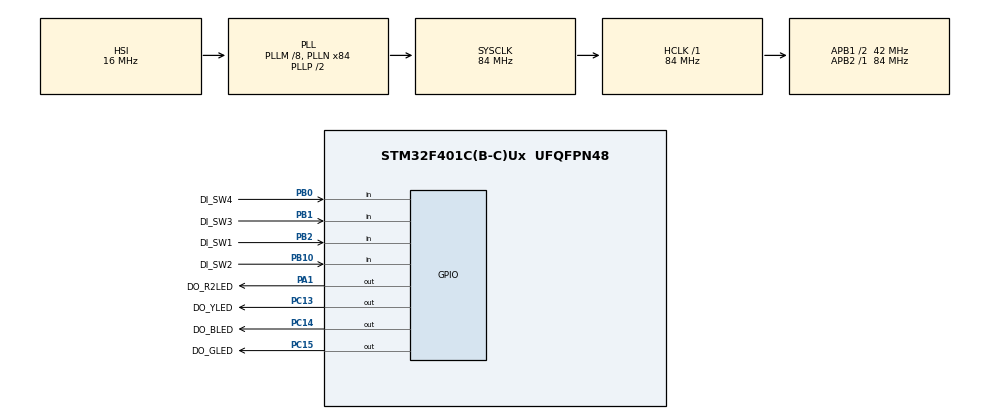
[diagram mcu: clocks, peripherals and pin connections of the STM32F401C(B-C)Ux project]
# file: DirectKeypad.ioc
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Mcu.Family=STM32F4
Mcu.Name=STM32F401C(B-C)Ux
Mcu.Package=UFQFPN48
NVIC.PriorityGroup=NVIC_PRIORITYGROUP_4
PA1.GPIO_Label=DO_R2LED
PA1.Signal=GPIO_Output
PA13.Mode=Serial_Wire
PA13.Signal=SYS_JTMS-SWDIO
PA14.Mode=Serial_Wire
PA14.Signal=SYS_JTCK-SWCLK
PB0.GPIO_Label=DI_SW4
PB0.GPIO_PuPd=GPIO_PULLUP
PB0.Signal=GPIO_Input
PB1.GPIO_Label=DI_SW3
PB1.GPIO_PuPd=GPIO_PULLUP
PB1.Signal=GPIO_Input
PB10.GPIO_Label=DI_SW2
PB10.GPIO_PuPd=GPIO_PULLUP
PB10.Signal=GPIO_Input
PB2.GPIO_Label=DI_SW1
PB2.GPIO_PuPd=GPIO_PULLUP
PB2.Signal=GPIO_Input
PC13-ANTI_TAMP.GPIO_Label=DO_YLED
PC13-ANTI_TAMP.Signal=GPIO_Output
PC14-OSC32_IN.GPIO_Label=DO_BLED
PC14-OSC32_IN.Signal=GPIO_Output
PC15-OSC32_OUT.GPIO_Label=DO_GLED
PC15-OSC32_OUT.Signal=GPIO_Output
PH0\ -\ OSC_IN.Mode=HSE-External-Oscillator
PH0\ -\ OSC_IN.Signal=RCC_OSC_IN
PH1\ -\ OSC_OUT.Mode=HSE-External-Oscillator
PH1\ -\ OSC_OUT.Signal=RCC_OSC_OUT
ProjectManager.HeapSize=0x200
ProjectManager.StackSize=0x400
ProjectManager.TargetToolchain=STM32CubeIDE
RCC.48MHZClocksFreq_Value=42000000
RCC.AHBFreq_Value=84000000
RCC.APB1CLKDivider=RCC_HCLK_DIV2
RCC.APB1Freq_Value=42000000
RCC.APB1TimFreq_Value=84000000
RCC.APB2Freq_Value=84000000
RCC.APB2TimFreq_Value=84000000
RCC.CortexFreq_Value=84000000
RCC.HCLKFreq_Value=84000000
RCC.HSE_VALUE=25000000
RCC.HSI_VALUE=16000000
RCC.LSE_VALUE=32768
RCC.PLLM=8
RCC.PLLN=84
RCC.SYSCLKFreq_VALUE=84000000
RCC.SYSCLKSource=RCC_SYSCLKSOURCE_PLLCLK
RCC.VCOOutputFreq_Value=168000000
board=custom

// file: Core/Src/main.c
/* USER CODE BEGIN Header */
/**
  ******************************************************************************
  * @file           : main.c
  * @brief          : Main program body
  ******************************************************************************
  * @attention
  *
  * Copyright (c) 2024 STMicroelectronics.
  * All rights reserved.
  *
  * This software is licensed under terms that can be found in the LICENSE file
  * in the root directory of this software component.
  * If no LICENSE file comes with this software, it is provided AS-IS.
  *
  ******************************************************************************
  */
/* USER CODE END Header */
#include "main.h"

void SystemClock_Config(void);
static void MX_GPIO_Init(void);

int main(void)
{

  /* MCU Configuration--------------------------------------------------------*/

  /* Reset of all peripherals, Initializes the Flash interface and the Systick. */
  HAL_Init();

  /* Configure the system clock */
  SystemClock_Config();

  /* Initialize all configured peripherals */
  MX_GPIO_Init();

  /* Infinite loop */
  /* USER CODE BEGIN WHILE */
  while (1)
  {
	  if(HAL_GPIO_ReadPin(DI_SW1_GPIO_Port, DI_SW1_Pin)==0)
	  {
		  HAL_GPIO_TogglePin(DO_R2LED_GPIO_Port, DO_R2LED_Pin);
		  HAL_Delay(200);
	  }
	  else if(HAL_GPIO_ReadPin(DI_SW2_GPIO_Port, DI_SW2_Pin)==0)
	  {
		  HAL_GPIO_TogglePin(DO_GLED_GPIO_Port, DO_GLED_Pin);
		  HAL_Delay(200);
	  }
	  else if(HAL_GPIO_ReadPin(DI_SW3_GPIO_Port, DI_SW3_Pin)==0)
	  {
		  HAL_GPIO_TogglePin(DO_BLED_GPIO_Port, DO_BLED_Pin);
		  HAL_Delay(200);
	  }
	  else if(HAL_GPIO_ReadPin(DI_SW4_GPIO_Port, DI_SW4_Pin)==0)
	  {
		  HAL_GPIO_TogglePin(DO_YLED_GPIO_Port, DO_YLED_Pin);
		  HAL_Delay(200);
	  }
    /* USER CODE END WHILE */

  }
}

void SystemClock_Config(void)
{
  RCC_OscInitTypeDef RCC_OscInitStruct = {0};
  RCC_ClkInitTypeDef RCC_ClkInitStruct = {0};

  /** Configure the main internal regulator output voltage
  */
  __HAL_RCC_PWR_CLK_ENABLE();
  __HAL_PWR_VOLTAGESCALING_CONFIG(PWR_REGULATOR_VOLTAGE_SCALE2);
  /** Initializes the RCC Oscillators according to the specified parameters
  * in the RCC_OscInitTypeDef structure.
  */
  RCC_OscInitStruct.OscillatorType = RCC_OSCILLATORTYPE_HSI;
  RCC_OscInitStruct.HSIState = RCC_HSI_ON;
  RCC_OscInitStruct.HSICalibrationValue = RCC_HSICALIBRATION_DEFAULT;
  RCC_OscInitStruct.PLL.PLLState = RCC_PLL_ON;
  RCC_OscInitStruct.PLL.PLLSource = RCC_PLLSOURCE_HSI;
  RCC_OscInitStruct.PLL.PLLM = 8;
  RCC_OscInitStruct.PLL.PLLN = 84;
  RCC_OscInitStruct.PLL.PLLP = RCC_PLLP_DIV2;
  RCC_OscInitStruct.PLL.PLLQ = 4;
  if (HAL_RCC_OscConfig(&RCC_OscInitStruct) != HAL_OK)
  {
    Error_Handler();
  }
  /** Initializes the CPU, AHB and APB buses clocks
  */
  RCC_ClkInitStruct.ClockType = RCC_CLOCKTYPE_HCLK|RCC_CLOCKTYPE_SYSCLK
                              |RCC_CLOCKTYPE_PCLK1|RCC_CLOCKTYPE_PCLK2;
  RCC_ClkInitStruct.SYSCLKSource = RCC_SYSCLKSOURCE_PLLCLK;
  RCC_ClkInitStruct.AHBCLKDivider = RCC_SYSCLK_DIV1;
  RCC_ClkInitStruct.APB1CLKDivider = RCC_HCLK_DIV2;
  RCC_ClkInitStruct.APB2CLKDivider = RCC_HCLK_DIV1;

  if (HAL_RCC_ClockConfig(&RCC_ClkInitStruct, FLASH_LATENCY_2) != HAL_OK)
  {
    Error_Handler();
  }
}

static void MX_GPIO_Init(void)
{
  GPIO_InitTypeDef GPIO_InitStruct = {0};

  /* GPIO Ports Clock Enable */
  __HAL_RCC_GPIOC_CLK_ENABLE();
  __HAL_RCC_GPIOH_CLK_ENABLE();
  __HAL_RCC_GPIOA_CLK_ENABLE();
  __HAL_RCC_GPIOB_CLK_ENABLE();

  /*Configure GPIO pin Output Level */
  HAL_GPIO_WritePin(GPIOC, DO_YLED_Pin|DO_BLED_Pin|DO_GLED_Pin, GPIO_PIN_RESET);

  /*Configure GPIO pin Output Level */
  HAL_GPIO_WritePin(DO_R2LED_GPIO_Port, DO_R2LED_Pin, GPIO_PIN_RESET);

  /*Configure GPIO pins : DO_YLED_Pin DO_BLED_Pin DO_GLED_Pin */
  GPIO_InitStruct.Pin = DO_YLED_Pin|DO_BLED_Pin|DO_GLED_Pin;
  GPIO_InitStruct.Mode = GPIO_MODE_OUTPUT_PP;
  GPIO_InitStruct.Pull = GPIO_NOPULL;
  GPIO_InitStruct.Speed = GPIO_SPEED_FREQ_LOW;
  HAL_GPIO_Init(GPIOC, &GPIO_InitStruct);

  /*Configure GPIO pin : DO_R2LED_Pin */
  GPIO_InitStruct.Pin = DO_R2LED_Pin;
  GPIO_InitStruct.Mode = GPIO_MODE_OUTPUT_PP;
  GPIO_InitStruct.Pull = GPIO_NOPULL;
  GPIO_InitStruct.Speed = GPIO_SPEED_FREQ_LOW;
  HAL_GPIO_Init(DO_R2LED_GPIO_Port, &GPIO_InitStruct);

  /*Configure GPIO pins : DI_SW4_Pin DI_SW3_Pin DI_SW1_Pin DI_SW2_Pin */
  GPIO_InitStruct.Pin = DI_SW4_Pin|DI_SW3_Pin|DI_SW1_Pin|DI_SW2_Pin;
  GPIO_InitStruct.Mode = GPIO_MODE_INPUT;
  GPIO_InitStruct.Pull = GPIO_PULLUP;
  HAL_GPIO_Init(GPIOB, &GPIO_InitStruct);

}

void Error_Handler(void)
{
  __disable_irq();
  while (1)
  {
  }
}
